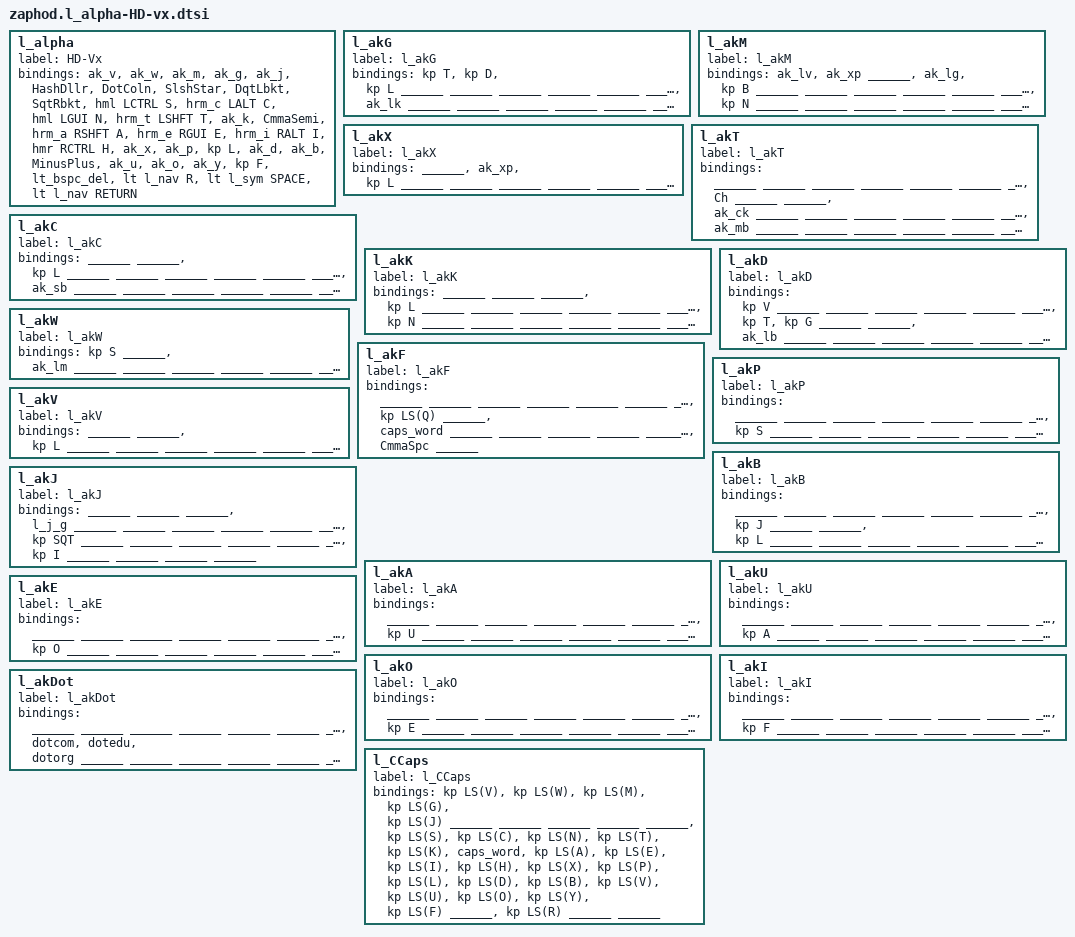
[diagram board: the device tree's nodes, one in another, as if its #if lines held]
#define ______  &trans

/*  Base (alpha) Layer  Hands Down Vibranium-vx
        Building for a 34 key board
╭─────────────────────╮ ╭──────────────────────╮
│  V   W   M   G   J  │ │  #$  .:  /*  "[  ']  │
│  S   C   N   T   K  | |  ,;   A   E   I   H  │
│  X   P   L   D   B  │ │  -+   U   O   Y   F  │
╰──────────╮  BSP  R  │ │  SPC RET  ╭──────────╯
           ╰──────────╯ ╰───────────╯
*/

                l_alpha {
                        label = "HD-Vx";
                        bindings = <

&ak_v        &ak_w           &ak_m        &ak_g          &ak_j         &HashDllr   &DotColn        &SlshStar      &DqtLbkt       &SqtRbkt
&hml LCTRL S &hrm_c LALT C   &hml LGUI N  &hrm_t LSHFT T &ak_k         &CmmaSemi   &hrm_a RSHFT A  &hrm_e RGUI E  &hrm_i RALT I  &hmr RCTRL H
&ak_x        &ak_p           &kp L        &ak_d          &ak_b         &MinusPlus  &ak_u           &ak_o          &ak_y          &kp F

                &lt_bspc_del &lt l_nav R      &lt l_sym SPACE &lt l_nav RETURN
                        >;
                };

                l_akG {
                        label = "l_akG";
                        bindings = <

&kp T   &kp D   &kp L   ______  ______      ______  ______  ______  ______  ______
______  ______  ______  ______  &ak_lk      ______  ______  ______  ______  ______
______  ______  ______  ______  ______      ______  ______  ______  ______  ______
                        ______  ______      ______  ______
                        >;
                };
                l_akM {
                        label = "l_akM";
                        bindings = <

&ak_lv  &ak_xp  ______  &ak_lg  &kp B       ______  ______  ______  ______  ______
______  ______  ______  ______  ______      ______  ______  ______  ______  &kp N
______  ______  ______  ______  ______      ______  ______  ______  ______  ______
                        ______  ______      ______  ______
                        >;
                };
                l_akX {
                        label = "l_akX";
                        bindings = <

______  &ak_xp  &kp L   ______  ______      ______  ______  ______  ______  ______
______  ______  ______  ______  ______      ______  ______  ______  ______  ______
______  ______  ______  ______  ______      ______  ______  ______  ______  ______
                        ______  ______      ______  ______
                        >;
                };
                l_akT {
                        label = "l_akT";
                        bindings = <

______  ______  ______  ______  ______      ______  ______  ______  ______  ______
______  &Ch     ______  ______  &ak_ck      ______  ______  ______  ______  ______
______  ______  ______  ______  &ak_mb      ______  ______  ______  ______  ______
                        ______  ______      ______  ______
                        >;
                };
                l_akC {
                        label = "l_akC";
                        bindings = <
______  ______  &kp L   ______  ______      ______  ______  ______  ______  ______
______  ______  ______  ______  ______      ______  ______  ______  ______  ______
&ak_sb  ______  ______  ______  ______      ______  ______  ______  ______  ______
                        ______  ______      ______  ______
                        >;
                };
                l_akK {
                        label = "l_akK";
                        bindings = <

______  ______  ______  &kp L   ______      ______  ______  ______  ______  ______
______  ______  ______  &kp N   ______      ______  ______  ______  ______  ______
______  ______  ______  ______  ______      ______  ______  ______  ______  ______
                        ______  ______      ______  ______
                        >;
                };
                l_akD {
                        label = "l_akD";
                        bindings = <

&kp V   ______  ______  ______  ______      ______  ______  ______  ______  ______
______  ______  ______  ______  ______      ______  ______  ______  ______  ______
&kp T   &kp G   ______  ______  &ak_lb      ______  ______  ______  ______  ______
                        ______  ______      ______  ______
                        >;
                };
                l_akW {
                        label = "l_akW";
                        bindings = <

&kp S   ______  &ak_lm  ______  ______      ______  ______  ______  ______  ______
______  ______  ______  ______  ______      ______  ______  ______  ______  ______
______  ______  ______  ______  ______      ______  ______  ______  ______  ______
                        ______  ______      ______  ______
                        >;
                };
                l_akF {
                        label = "l_akF";
                        bindings = <
______  ______  ______  ______  ______      ______  ______  ______  ______  ______
______  ______  ______  &kp LS(Q) ______    &caps_word  ______  ______  ______  ______
______  ______  ______  ______  ______      ______  ______  ______  ______  ______
                        ______  ______      &CmmaSpc  ______
                        >;
                };
                l_akP {
                        label = "l_akP";
                        bindings = <
______  ______  ______  ______  ______      ______  ______  ______  ______  ______
______  ______  ______  ______  ______      ______  ______  ______  ______  ______
&kp S   ______  ______  ______  ______      ______  ______  ______  ______  ______
                        ______  ______      ______  ______
                        >;
                };
                l_akB {
                        label = "l_akB";
                        bindings = <
______  ______  ______  ______  ______      ______  ______  ______  ______  ______
______  ______  ______  ______  ______      ______  ______  ______  ______  ______
&kp J   ______  ______  &kp L   ______      ______  ______  ______  ______  ______
                        ______  ______      ______  ______
                        >;
                };
                l_akV {
                        label = "l_akV";
                        bindings = <

______  ______  &kp L   ______  ______      ______  ______  ______  ______  ______
______  ______  ______  ______  ______      ______  ______  ______  ______  ______
______  ______  ______  ______  ______      ______  ______  ______  ______  ______
                        ______  ______      ______  ______
                        >;
                };
                l_akJ {
                        label = "l_akJ";
                        bindings = <

______  ______  ______  &l_j_g  ______      ______  ______  ______  ______  ______
______  ______  ______  ______  ______      ______  ______  ______  ______  &kp SQT
______  ______  ______  ______  ______      ______  ______  ______  ______  &kp I
                        ______  ______      ______  ______
                        >;
                };



                l_akA {
                        label = "l_akA";
                        bindings = <

______  ______  ______  ______  ______      ______  ______  ______  ______  &kp U
______  ______  ______  ______  ______      ______  ______  ______  ______  ______
______  ______  ______  ______  ______      ______  ______  ______  ______  ______
                        ______  ______      ______  ______
                        >;
                };

                l_akU {
                        label = "l_akU";
                        bindings = <

______  ______  ______  ______  ______      ______  ______  ______  ______  &kp A
______  ______  ______  ______  ______      ______  ______  ______  ______  ______
______  ______  ______  ______  ______      ______  ______  ______  ______  ______
                        ______  ______      ______  ______
                        >;
                };

                l_akE {
                        label = "l_akE";
                        bindings = <

______  ______  ______  ______  ______      ______  ______  ______  ______  ______
______  ______  ______  ______  ______      ______  ______  ______  ______  &kp O
______  ______  ______  ______  ______      ______  ______  ______  ______  ______
                        ______  ______      ______  ______
                        >;
                };
                l_akO {
                        label = "l_akO";
                        bindings = <

______  ______  ______  ______  ______      ______  ______  ______  ______  &kp E
______  ______  ______  ______  ______      ______  ______  ______  ______  ______
______  ______  ______  ______  ______      ______  ______  ______  ______  ______
                        ______  ______      ______  ______
                        >;
                };
                l_akI {
                        label = "l_akI";
                        bindings = <

______  ______  ______  ______  ______      ______  ______  ______  ______  ______
______  ______  ______  ______  ______      ______  ______  ______  ______  &kp F
______  ______  ______  ______  ______      ______  ______  ______  ______  ______
                        ______  ______      ______  ______
                        >;
                };

                l_akDot {
                        label = "l_akDot";
                        bindings = <

______  ______  ______  ______  ______      ______  ______  &dotcom &dotedu &dotorg
______  ______  ______  ______  ______      ______  ______  ______  ______  ______
______  ______  ______  ______  ______      ______  ______  ______  ______  ______
                        ______  ______      ______  ______
                        >;
                };

#ifdef COMMA_CAP2
                l_CCaps {
                        label = "l_CCaps";
                        bindings = <

&kp LS(V)   &kp LS(W)   &kp LS(M)   &kp LS(G)   &kp LS(J)       ______  ______  ______  ______  ______
&kp LS(S)   &kp LS(C)   &kp LS(N)   &kp LS(T)   &kp LS(K)       &caps_word   &kp LS(A)   &kp LS(E)   &kp LS(I)   &kp LS(H)
&kp LS(X)   &kp LS(P)   &kp LS(L)   &kp LS(D)   &kp LS(B)       &kp LS(V)   &kp LS(U)   &kp LS(O)   &kp LS(Y)   &kp LS(F)
                        ______  &kp LS(R)       ______  ______
                        >;
                };

#endif
